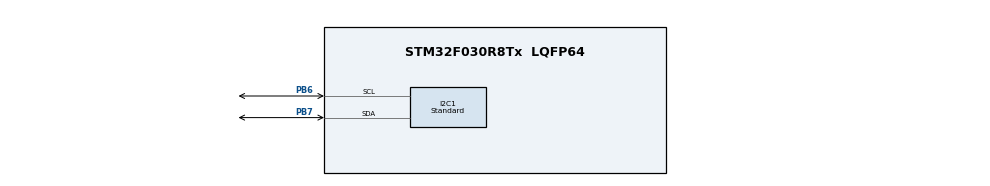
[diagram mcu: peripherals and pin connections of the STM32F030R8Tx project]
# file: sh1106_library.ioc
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Dma.I2C1_TX.0.Direction=DMA_MEMORY_TO_PERIPH
Dma.I2C1_TX.0.Instance=DMA1_Channel2
Dma.I2C1_TX.0.MemDataAlignment=DMA_MDATAALIGN_BYTE
Dma.I2C1_TX.0.MemInc=DMA_MINC_ENABLE
Dma.I2C1_TX.0.Mode=DMA_NORMAL
Dma.I2C1_TX.0.PeriphDataAlignment=DMA_PDATAALIGN_BYTE
Dma.I2C1_TX.0.PeriphInc=DMA_PINC_DISABLE
Dma.I2C1_TX.0.Priority=DMA_PRIORITY_LOW
Dma.Request0=I2C1_TX
I2C1.I2C_Speed_Mode=I2C_Standard
I2C1.Timing=0x00201D2B
Mcu.Family=STM32F0
Mcu.Name=STM32F030R8Tx
Mcu.Package=LQFP64
NVIC.DMA1_Channel2_3_IRQn=true\:0\:0\:false\:false\:true\:false\:true\:true
NVIC.I2C1_IRQn=true\:0\:0\:false\:false\:true\:true\:true\:true
PB6.GPIO_Pu=GPIO_PULLUP
PB6.Mode=I2C
PB6.Signal=I2C1_SCL
PB7.GPIO_Pu=GPIO_PULLUP
PB7.Mode=I2C
PB7.Signal=I2C1_SDA
ProjectManager.HeapSize=0x200
ProjectManager.StackSize=0x400
ProjectManager.TargetToolchain=STM32CubeIDE
board=custom

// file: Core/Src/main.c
/* USER CODE BEGIN Header */
/**
  ******************************************************************************
  * @file           : main.c
  * @brief          : Main program body
  ******************************************************************************
  * @attention
  *
  * Copyright (c) 2024 STMicroelectronics.
  * All rights reserved.
  *
  * This software is licensed under terms that can be found in the LICENSE file
  * in the root directory of this software component.
  * If no LICENSE file comes with this software, it is provided AS-IS.
  *
  ******************************************************************************
  */
/* USER CODE END Header */
#include "main.h"

/* USER CODE BEGIN Includes */
#include <stdint.h>
#include <sh1106.h>

/* USER CODE END Includes */

/* USER CODE BEGIN PD */
#define SH1106_DEV_ADDRESS 0x78

/* USER CODE END PD */

I2C_HandleTypeDef hi2c1;
DMA_HandleTypeDef hdma_i2c1_tx;

void SystemClock_Config(void);
static void MX_GPIO_Init(void);
static void MX_DMA_Init(void);
static void MX_I2C1_Init(void);

int main(void) {

  /* MCU Configuration--------------------------------------------------------*/

  /* Reset of all peripherals, Initializes the Flash interface and the Systick. */
  HAL_Init();

  /* Configure the system clock */
  SystemClock_Config();

  /* Initialize all configured peripherals */
  MX_GPIO_Init();
  MX_DMA_Init();
  MX_I2C1_Init();
  /* USER CODE BEGIN 2 */

/* USER CODE BEGIN 2 */
  SH1106_Init(&hi2c1, SH1106_DEV_ADDRESS);
  SH1106_Display_Clear();
  SH1106_Display_On();

  SH1106_Draw_Line(100, 63, 12, 5);
  SH1106_Draw_Line(23, 15, 96, 18);
  SH1106_Draw_Line(0, 55, 85, 38);
  SH1106_Draw_Line(68, 3, 22, 52);

  /* USER CODE END 2 */

  /* Infinite loop */
  while(1) {

  }
}

void SystemClock_Config(void)
{
  RCC_OscInitTypeDef RCC_OscInitStruct = {0};
  RCC_ClkInitTypeDef RCC_ClkInitStruct = {0};
  RCC_PeriphCLKInitTypeDef PeriphClkInit = {0};

  /** Initializes the RCC Oscillators according to the specified parameters
  * in the RCC_OscInitTypeDef structure.
  */
  RCC_OscInitStruct.OscillatorType = RCC_OSCILLATORTYPE_HSI;
  RCC_OscInitStruct.HSIState = RCC_HSI_ON;
  RCC_OscInitStruct.HSICalibrationValue = RCC_HSICALIBRATION_DEFAULT;
  RCC_OscInitStruct.PLL.PLLState = RCC_PLL_NONE;
  if (HAL_RCC_OscConfig(&RCC_OscInitStruct) != HAL_OK)
  {
    Error_Handler();
  }

  /** Initializes the CPU, AHB and APB buses clocks
  */
  RCC_ClkInitStruct.ClockType = RCC_CLOCKTYPE_HCLK|RCC_CLOCKTYPE_SYSCLK
                              |RCC_CLOCKTYPE_PCLK1;
  RCC_ClkInitStruct.SYSCLKSource = RCC_SYSCLKSOURCE_HSI;
  RCC_ClkInitStruct.AHBCLKDivider = RCC_SYSCLK_DIV1;
  RCC_ClkInitStruct.APB1CLKDivider = RCC_HCLK_DIV1;

  if (HAL_RCC_ClockConfig(&RCC_ClkInitStruct, FLASH_LATENCY_0) != HAL_OK)
  {
    Error_Handler();
  }
  PeriphClkInit.PeriphClockSelection = RCC_PERIPHCLK_I2C1;
  PeriphClkInit.I2c1ClockSelection = RCC_I2C1CLKSOURCE_HSI;
  if (HAL_RCCEx_PeriphCLKConfig(&PeriphClkInit) != HAL_OK)
  {
    Error_Handler();
  }
}

static void MX_I2C1_Init(void)
{

  hi2c1.Instance = I2C1;
  hi2c1.Init.Timing = 0x00201D2B;
  hi2c1.Init.OwnAddress1 = 0;
  hi2c1.Init.AddressingMode = I2C_ADDRESSINGMODE_7BIT;
  hi2c1.Init.DualAddressMode = I2C_DUALADDRESS_DISABLE;
  hi2c1.Init.OwnAddress2 = 0;
  hi2c1.Init.OwnAddress2Masks = I2C_OA2_NOMASK;
  hi2c1.Init.GeneralCallMode = I2C_GENERALCALL_DISABLE;
  hi2c1.Init.NoStretchMode = I2C_NOSTRETCH_DISABLE;
  if (HAL_I2C_Init(&hi2c1) != HAL_OK)
  {
    Error_Handler();
  }

  /** Configure Analogue filter
  */
  if (HAL_I2CEx_ConfigAnalogFilter(&hi2c1, I2C_ANALOGFILTER_ENABLE) != HAL_OK)
  {
    Error_Handler();
  }

  /** Configure Digital filter
  */
  if (HAL_I2CEx_ConfigDigitalFilter(&hi2c1, 0) != HAL_OK)
  {
    Error_Handler();
  }

}

static void MX_DMA_Init(void)
{

  /* DMA controller clock enable */
  __HAL_RCC_DMA1_CLK_ENABLE();

  /* DMA interrupt init */
  /* DMA1_Channel2_3_IRQn interrupt configuration */
  HAL_NVIC_SetPriority(DMA1_Channel2_3_IRQn, 0, 0);
  HAL_NVIC_EnableIRQ(DMA1_Channel2_3_IRQn);

}

static void MX_GPIO_Init(void)
{

  /* GPIO Ports Clock Enable */
  __HAL_RCC_GPIOB_CLK_ENABLE();

}

void Error_Handler(void)
{
  __disable_irq();
  while(1) {
  }
}
